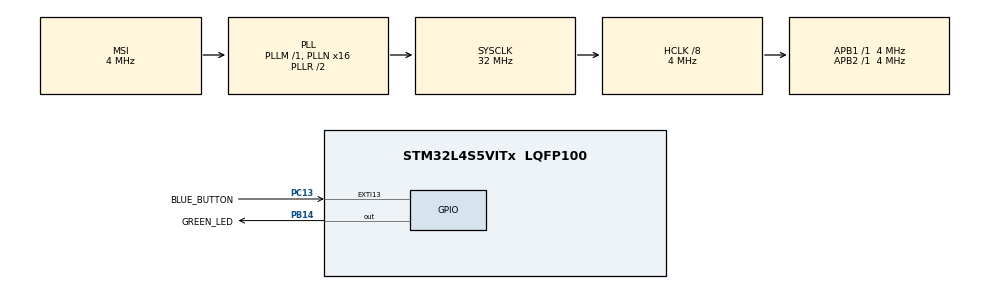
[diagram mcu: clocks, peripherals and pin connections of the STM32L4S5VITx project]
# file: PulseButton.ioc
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Mcu.Family=STM32L4
Mcu.Name=STM32L4S5VITx
Mcu.Package=LQFP100
NVIC.EXTI15_10_IRQn=true\:0\:0\:false\:false\:true\:true\:true\:true
NVIC.PriorityGroup=NVIC_PRIORITYGROUP_4
PB14.GPIO_Label=GREEN_LED
PB14.Signal=GPIO_Output
PC13.GPIO_Label=BLUE_BUTTON
PC13.GPIO_ModeDefaultEXTI=GPIO_MODE_IT_FALLING
PC13.Signal=GPXTI13
ProjectManager.HeapSize=0x200
ProjectManager.StackSize=0x400
ProjectManager.TargetToolchain=STM32CubeIDE
RCC.AHBCLKDivider=RCC_SYSCLK_DIV8
RCC.AHBFreq_Value=4000000
RCC.APB1Freq_Value=4000000
RCC.APB1TimFreq_Value=4000000
RCC.APB2Freq_Value=4000000
RCC.APB2TimFreq_Value=4000000
RCC.CortexFreq_Value=4000000
RCC.HCLKFreq_Value=4000000
RCC.HSE_VALUE=8000000
RCC.HSI48_VALUE=48000000
RCC.HSI_VALUE=16000000
RCC.LSE_VALUE=32768
RCC.MSI_VALUE=4000000
RCC.PLLN=16
RCC.SYSCLKFreq_VALUE=32000000
RCC.SYSCLKSource=RCC_SYSCLKSOURCE_PLLCLK
RCC.VCOOutputFreq_Value=64000000
board=custom

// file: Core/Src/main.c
/* USER CODE BEGIN Header */
/**
  ******************************************************************************
  * @file           : main.c
  * @brief          : Main program body
  ******************************************************************************
  * @attention
  *
  * Copyright (c) 2023 STMicroelectronics.
  * All rights reserved.
  *
  * This software is licensed under terms that can be found in the LICENSE file
  * in the root directory of this software component.
  * If no LICENSE file comes with this software, it is provided AS-IS.
  *
  ******************************************************************************
  */
/* USER CODE END Header */
#include "main.h"

/* USER CODE BEGIN PV */
uint8_t button_flag=0;
/* USER CODE END PV */

void SystemClock_Config(void);
static void MX_GPIO_Init(void);

int main(void)
{

  /* MCU Configuration--------------------------------------------------------*/

  /* Reset of all peripherals, Initializes the Flash interface and the Systick. */
  HAL_Init();

  /* Configure the system clock */
  SystemClock_Config();

  /* Initialize all configured peripherals */
  MX_GPIO_Init();

  /* Infinite loop */
  while (1)
  {
	  if (button_flag == 1){
		  HAL_GPIO_WritePin(GREEN_LED_GPIO_Port, GREEN_LED_Pin, GPIO_PIN_SET);
		  HAL_Delay(4000); // 4000ms = 4 seconds
		  button_flag = 0;
	  }
	  HAL_GPIO_WritePin(GREEN_LED_GPIO_Port, GREEN_LED_Pin, 0);
  }
}

void SystemClock_Config(void)
{
  RCC_OscInitTypeDef RCC_OscInitStruct = {0};
  RCC_ClkInitTypeDef RCC_ClkInitStruct = {0};

  /** Configure the main internal regulator output voltage
  */
  if (HAL_PWREx_ControlVoltageScaling(PWR_REGULATOR_VOLTAGE_SCALE1) != HAL_OK)
  {
    Error_Handler();
  }

  /** Initializes the RCC Oscillators according to the specified parameters
  * in the RCC_OscInitTypeDef structure.
  */
  RCC_OscInitStruct.OscillatorType = RCC_OSCILLATORTYPE_MSI;
  RCC_OscInitStruct.MSIState = RCC_MSI_ON;
  RCC_OscInitStruct.MSICalibrationValue = 0;
  RCC_OscInitStruct.MSIClockRange = RCC_MSIRANGE_6;
  RCC_OscInitStruct.PLL.PLLState = RCC_PLL_ON;
  RCC_OscInitStruct.PLL.PLLSource = RCC_PLLSOURCE_MSI;
  RCC_OscInitStruct.PLL.PLLM = 1;
  RCC_OscInitStruct.PLL.PLLN = 16;
  RCC_OscInitStruct.PLL.PLLP = RCC_PLLP_DIV2;
  RCC_OscInitStruct.PLL.PLLQ = RCC_PLLQ_DIV2;
  RCC_OscInitStruct.PLL.PLLR = RCC_PLLR_DIV2;
  if (HAL_RCC_OscConfig(&RCC_OscInitStruct) != HAL_OK)
  {
    Error_Handler();
  }

  /** Initializes the CPU, AHB and APB buses clocks
  */
  RCC_ClkInitStruct.ClockType = RCC_CLOCKTYPE_HCLK|RCC_CLOCKTYPE_SYSCLK
                              |RCC_CLOCKTYPE_PCLK1|RCC_CLOCKTYPE_PCLK2;
  RCC_ClkInitStruct.SYSCLKSource = RCC_SYSCLKSOURCE_PLLCLK;
  RCC_ClkInitStruct.AHBCLKDivider = RCC_SYSCLK_DIV8;
  RCC_ClkInitStruct.APB1CLKDivider = RCC_HCLK_DIV1;
  RCC_ClkInitStruct.APB2CLKDivider = RCC_HCLK_DIV1;

  if (HAL_RCC_ClockConfig(&RCC_ClkInitStruct, FLASH_LATENCY_0) != HAL_OK)
  {
    Error_Handler();
  }
}

static void MX_GPIO_Init(void)
{
  GPIO_InitTypeDef GPIO_InitStruct = {0};

  /* GPIO Ports Clock Enable */
  __HAL_RCC_GPIOC_CLK_ENABLE();
  __HAL_RCC_GPIOB_CLK_ENABLE();

  /*Configure GPIO pin Output Level */
  HAL_GPIO_WritePin(GREEN_LED_GPIO_Port, GREEN_LED_Pin, GPIO_PIN_RESET);

  /*Configure GPIO pin : BLUE_BUTTON_Pin */
  GPIO_InitStruct.Pin = BLUE_BUTTON_Pin;
  GPIO_InitStruct.Mode = GPIO_MODE_IT_FALLING;
  GPIO_InitStruct.Pull = GPIO_NOPULL;
  HAL_GPIO_Init(BLUE_BUTTON_GPIO_Port, &GPIO_InitStruct);

  /*Configure GPIO pin : GREEN_LED_Pin */
  GPIO_InitStruct.Pin = GREEN_LED_Pin;
  GPIO_InitStruct.Mode = GPIO_MODE_OUTPUT_PP;
  GPIO_InitStruct.Pull = GPIO_NOPULL;
  GPIO_InitStruct.Speed = GPIO_SPEED_FREQ_LOW;
  HAL_GPIO_Init(GREEN_LED_GPIO_Port, &GPIO_InitStruct);

  /* EXTI interrupt init*/
  HAL_NVIC_SetPriority(EXTI15_10_IRQn, 0, 0);
  HAL_NVIC_EnableIRQ(EXTI15_10_IRQn);

}

/* USER CODE BEGIN 4 */
void HAL_GPIO_EXTI_Callback(uint16_t GPIO_Pin){
	button_flag = 1;
}
/* USER CODE END 4 */

void Error_Handler(void)
{
  __disable_irq();
  while (1)
  {
  }
}
